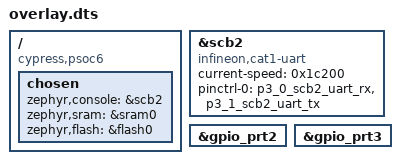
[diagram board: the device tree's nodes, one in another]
/ {
	compatible = "cypress,psoc6";
	chosen {
		zephyr,console = &scb2;
		zephyr,sram = &sram0;
		zephyr,flash = &flash0;
	};
};
&scb2{
	compatible = "infineon,cat1-uart";
	status = "okay";
	current-speed = < 0x1c200 >;
	pinctrl-0 = < &p3_0_scb2_uart_rx &p3_1_scb2_uart_tx >;
	pinctrl-names = "default";
};
&gpio_prt2{
	status = "okay";
};
&gpio_prt3{
	status = "okay";
};
